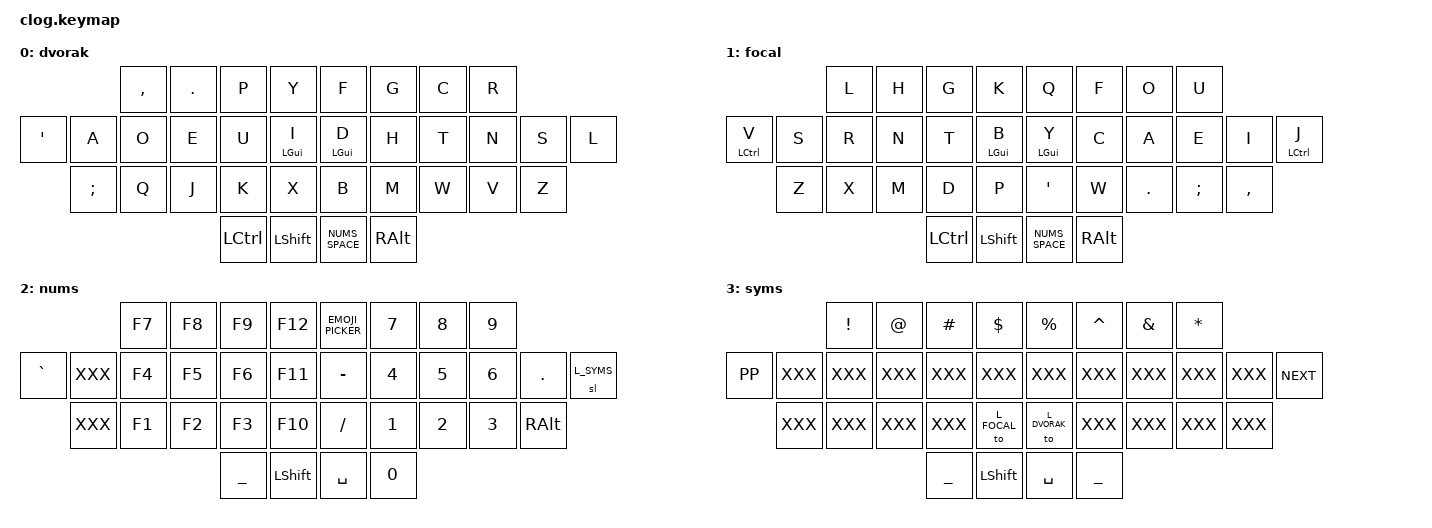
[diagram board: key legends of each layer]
/* source keypos definitions */
#include "zmk-helpers/key-labels/osprette.h"

/* source the main keymap */
#include "base.keymap"

#define L_DVORAK 0
#define L_FOCAL 1
#define L_NUMS 2
#define L_SYMS 3

/*                                     34 KEY MATRIX / LAYOUT MAPPING

           ╭───────────────┬────────────────╮                 ╭─────────────────┬─────────────────╮
  ╭────────╯ 0   1   2   3 │  4   5   6   7 ╰───────╮ ╭───────╯ LT3 LT2 LT1 LT0 │ RT0 RT1 RT2 RT3 ╰───────╮
  │  8   9  10  11  12  13 │ 14  15  16  17  18  19 │ │ LM5 LM4 LM3 LM2 LM1 LM0 │ RM0 RM1 RM2 RM3 RM4 RM5 │
  ╰───╮ 20  21  22  23  24 │ 25  26  27  28  29 ╭───╯ ╰───╮ LB4 LB3 LB2 LB1 LB0 │ RB0 RB1 RB2 RB3 RB4 ╭───╯
      ╰───────────╮ 30  31 │ 32  33 ╭───────────╯         ╰───────────╮ LH1 LH0 │ RH0 RH1 ╭───────────╯
                  ╰────────┴────────╯                                 ╰─────────┴─────────╯             */

ZMK_COMBO(c_lsuper, LG_ENTER, LM2 LM1, ALL, COMBO_JOINTLY_MS)
ZMK_COMBO(c_rsuper, RG_ENTER, RM1 RM2, L_NUMS, COMBO_JOINTLY_MS)

ZMK_COMBO(c_bksp, &kp BSPC, 6 7, ALL, COMBO_JOINTLY_MS)
ZMK_COMBO(c_del, &kp DEL, 4 6 7, ALL, COMBO_JOINTLY_MS)
ZMK_COMBO(c_esc, &kp ESC, LT3 LT2, ALL, COMBO_JOINTLY_MS)
ZMK_COMBO(c_grv, &kp GRAVE, LT3 LT2 LT0, ALL, COMBO_JOINTLY_MS)
ZMK_COMBO(c_tab, &kp TAB, LM5 LM4, ALL, COMBO_JOINTLY_MS)
ZMK_COMBO(c_ins, &kp INS, LM5 LM4 LB4, ALL, COMBO_JOINTLY_MS)
// See comments below about c_end for some more context on this.
ZMK_COMBO(c_mins, &kp MINUS, RM2 RM3, ALL, COMBO_JOINTLY_MS)
ZMK_COMBO(c_slsh, &kp SLASH, RB2 RB3, ALL, COMBO_JOINTLY_MS)
ZMK_COMBO(c_pipe, &kp BACKSLASH, RM0 RM2 RM3, ALL, COMBO_JOINTLY_MS) // RM5 busted. Patch to 19
ZMK_COMBO(c_plus, &kp PLUS, LB0 LB2 LB3, ALL, COMBO_JOINTLY_MS)
ZMK_COMBO(c_eql, &kp EQUAL, RB0 RB2 RB3, ALL, COMBO_JOINTLY_MS)
ZMK_COMBO(c_lprn, &kp LPAR, LT0 LT1, ALL, COMBO_JOINTLY_MS)
ZMK_COMBO(c_rprn, &kp RPAR, RT0 RT1, ALL, COMBO_JOINTLY_MS)
ZMK_COMBO(c_lbrk, &kp LBKT, LB0 LB1, ALL, COMBO_JOINTLY_MS)
ZMK_COMBO(c_rbrk, &kp RBKT, RB0 RB1, ALL, COMBO_JOINTLY_MS)
// c_lbrc and c_rbrc are implicit (and more forgiving of thumb timing) given LBKT/RBKT
// ([ ]) turning into { } with Shift
ZMK_COMBO(c_arrup, &kp UP, LT1 LT2, ALL, COMBO_JOINTLY_MS)
ZMK_COMBO(c_arrleft, &kp LEFT, LM2 LM3, ALL, COMBO_JOINTLY_MS)
// A secondary option since my hands always land here and want to press it anyway
ZMK_COMBO(c_arrleft2, &kp LEFT, LM4 LM3, ALL, COMBO_JOINTLY_MS)
ZMK_COMBO(c_arrright, &kp RIGHT, LM0 LM1, ALL, COMBO_JOINTLY_MS)
ZMK_COMBO(c_arrdown, &kp DOWN, LB1 LB2, ALL, COMBO_JOINTLY_MS)
ZMK_COMBO(c_pgup, &kp PG_UP, RT1 RT2, ALL, COMBO_JOINTLY_MS)
ZMK_COMBO(c_home, &kp HOME, RM0 RM1, ALL, COMBO_JOINTLY_MS)
// End key is asymmetrical with the arrow key cluster but makes room for RM2+RM3
// dash, which feels way better on Choc spacing than what I originally had designed.
ZMK_COMBO(c_end, &kp END, RM2 19, ALL, COMBO_JOINTLY_MS)
ZMK_COMBO(c_pgdn, &kp PG_DN, RB1 RB2, ALL, COMBO_JOINTLY_MS)
ZMK_COMBO(c_supup, &kp LG(UP), LT3 LT2 LT1, ALL, COMBO_JOINTLY_MS)
ZMK_COMBO(c_supleft, &kp LG(LEFT), LM3 LM2 LM1, ALL, COMBO_JOINTLY_MS)
ZMK_COMBO(c_supright, &kp LG(RIGHT), LM2 LM1 LM0, ALL, COMBO_JOINTLY_MS) // Was LMB0. Assumed LM0
ZMK_COMBO(c_supdn, &kp LG(DOWN), LB3 LB2 LB1, ALL, COMBO_JOINTLY_MS)
ZMK_COMBO(c_lockscreen, &kp LG(HOME), RM0 RM1 RM2, ALL, COMBO_JOINTLY_MS)
ZMK_COMBO(c_closewin, &kp LG(END), RM0 RM2 19, ALL, COMBO_JOINTLY_MS)
ZMK_COMBO(c_mfa, &kp LG(O), LT2 LT1 LT0, ALL, COMBO_JOINTLY_MS)
ZMK_COMBO(c_pwd, &kp LG(LC(O)), RT0 RT1 RT2, ALL, COMBO_JOINTLY_MS)
ZMK_COMBO(c_brightup, &kp C_BRI_UP, RT1 RT2 RT3, ALL, COMBO_JOINTLY_MS)
ZMK_COMBO(c_brightdn, &kp C_BRI_DN, RB1 RB2 RB3, ALL, COMBO_JOINTLY_MS)
ZMK_COMBO(c_voldn, &kp K_VOL_DN, LB2 LB1 LB0, ALL, COMBO_JOINTLY_MS)
ZMK_COMBO(c_volup, &kp K_VOL_UP, RB0 RB1 RB2, ALL, COMBO_JOINTLY_MS)

ZMK_COMBO(c_volmute, &kp K_MUTE, LB2 LB1 LB0 RB0 RB1 RB2, ALL, COMBO_LAZILY_MS)
ZMK_COMBO(c_syms, &mo L_SYMS, LH0 RH0, ALL, COMBO_LAZILY_MS)
ZMK_COMBO(c_bootloader, &bootloader, 8 9 20 31 32 18 19 29, ALL, COMBO_LAZILY_MS)

/* Keymap */

ZMK_LAYER(dvorak,
//                             ╭─────────────┬─────────────┬─────────────┬─────────────╮ ╭─────────────┬─────────────┬─────────────┬─────────────╮
                                 &kp COMMA     &kp DOT       &kp P         &kp Y           &kp F         &kp G         &kp C         &kp R
// ╭─────────────┬─────────────┼─────────────┼─────────────┼─────────────┼─────────────┤ ├─────────────┼─────────────┼─────────────┼─────────────┼─────────────┬─────────────╮
     &kp SQT       &kp A         &kp O         &kp E         &kp U         &hml LGUI I     &hmr LGUI D   &kp H         &kp T         &kp N         &kp S         &kp L
// ╰─────────────├─────────────┼─────────────┼─────────────┼─────────────┼─────────────┤ ├─────────────┼─────────────┼─────────────┼─────────────┼─────────────┤─────────────╯
                   &kp SEMICOLON &kp Q         &kp J         &kp K         &kp X           &kp B         &kp M         &kp W         &kp V         &kp Z
//               ╰─────────────┴─────────────┴─────────────┼─────────────┼─────────────┤ ├─────────────┼─────────────┼─────────────┴─────────────┴─────────────╯
                                                             &kp LCTL      &kp LSHFT       NUMS_SPACE    &kp RALT
//                                                         ╰─────────────┴─────────────╯ ╰─────────────┴─────────────╯
)

ZMK_LAYER(focal,
//                             ╭─────────────┬─────────────┬─────────────┬─────────────╮ ╭─────────────┬─────────────┬─────────────┬─────────────╮
                                 &kp L         &kp H         &kp G         &kp K           &kp Q         &kp F         &kp O         &kp U
// ╭─────────────┬─────────────┼─────────────┼─────────────┼─────────────┼─────────────┤ ├─────────────┼─────────────┼─────────────┼─────────────┼─────────────┬─────────────╮
     &hmr LCTL V   &kp S         &kp R         &kp N         &kp T         &hml LGUI B     &hmr LGUI Y   &kp C         &kp A         &kp E         &kp I         &hmr LCTL J
// ╰─────────────├─────────────┼─────────────┼─────────────┼─────────────┼─────────────┤ ├─────────────┼─────────────┼─────────────┼─────────────┼─────────────┤─────────────╯
                   &kp Z         &kp X         &kp M         &kp D         &kp P           &kp SQT       &kp W         &kp DOT       &kp SEMICOLON &kp COMMA
//               ╰─────────────┴─────────────┴─────────────┼─────────────┼─────────────┤ ├─────────────┼─────────────┼─────────────┴─────────────┴─────────────╯
                                                             &kp LCTL      &kp LSHFT       NUMS_SPACE    &kp RALT
//                                                         ╰─────────────┴─────────────╯ ╰─────────────┴─────────────╯
)

ZMK_LAYER(nums,
//                             ╭─────────────┬─────────────┬─────────────┬─────────────╮ ╭─────────────┬─────────────┬─────────────┬─────────────╮
                                 &kp F7        &kp F8        &kp F9        &kp F12         EMOJI_PICKER  &kp N7         &kp N8        &kp N9
// ╭─────────────┬─────────────┼─────────────┼─────────────┼─────────────┼─────────────┤ ├─────────────┼─────────────┼─────────────┼─────────────┼─────────────┬─────────────╮
     &kp GRAVE     XXX           &kp F4        &kp F5        &kp F6        &kp F11         &kp MINUS     &kp N4         &kp N5        &kp N6        &kp DOT       &sl L_SYMS
// ╰─────────────├─────────────┼─────────────┼─────────────┼─────────────┼─────────────┤ ├─────────────┼─────────────┼─────────────┼─────────────┼─────────────┤─────────────╯
                   XXX           &kp F1        &kp F2        &kp F3        &kp F10         &kp SLASH     &kp N1         &kp N2        &kp N3        &kp RALT
//               ╰─────────────┴─────────────┴─────────────┼─────────────┼─────────────┤ ├─────────────┼─────────────┼─────────────┴─────────────┴─────────────╯
                                                             ___           &kp LSHFT       &kp SPACE     &kp N0
//                                                         ╰─────────────┴─────────────╯ ╰─────────────┴─────────────╯
)

ZMK_LAYER(syms,
//                             ╭─────────────┬─────────────┬─────────────┬─────────────╮ ╭─────────────┬─────────────┬─────────────┬─────────────╮
                                 &kp EXCL      &kp AT        &kp POUND     &kp DLLR        &kp PRCNT     &kp CARET     &kp AMPS      &kp STAR
// ╭─────────────┬─────────────┼─────────────┼─────────────┼─────────────┼─────────────┤ ├─────────────┼─────────────┼─────────────┼─────────────┼─────────────┬─────────────╮
     &kp K_PP      XXX           XXX           XXX           XXX           XXX             XXX           XXX           XXX           XXX           XXX           &kp K_NEXT
// ╰─────────────├─────────────┼─────────────┼─────────────┼─────────────┼─────────────┤ ├─────────────┼─────────────┼─────────────┼─────────────┼─────────────┤─────────────╯
                   XXX           XXX           XXX           XXX           &to L_FOCAL     &to L_DVORAK  XXX           XXX           XXX           XXX
//               ╰─────────────┴─────────────┴─────────────┼─────────────┼─────────────┤ ├─────────────┼─────────────┼─────────────┴─────────────┴─────────────╯
                                                             ___           &kp LSHFT       &kp SPACE     ___
//                                                         ╰─────────────┴─────────────╯ ╰─────────────┴─────────────╯
)

/* vim: set ft=c tw=174: */
